VERSION "ETH_Backbone_CAN_STUB_v2.1"

NS_ :

BS_:

BU_: EMS_POLICE_TX EMS_AMB_TX EMS_ALERT_RX ETH_SW WARN_ARB_MGR ADAS_WARN_CTRL NAV_CTX_MGR IVI_GW CHS_GW VAL_SCENARIO_CTRL DOMAIN_BOUNDARY_MGR Vector__XXX

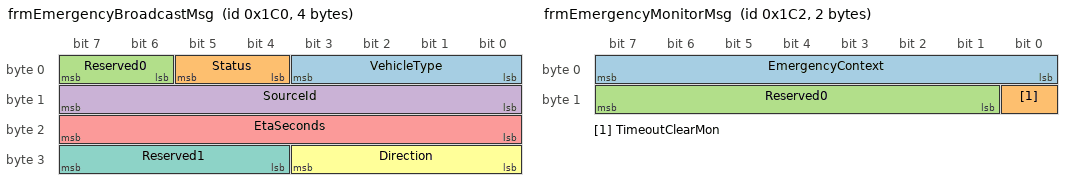
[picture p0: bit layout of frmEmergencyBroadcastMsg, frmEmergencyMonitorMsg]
BO_ 448 frmEmergencyBroadcastMsg: 4 Vector__XXX
 SG_ VehicleType  : 0|4@1+  (1,0) [0|15]  ""    EMS_ALERT_RX
 SG_ Status       : 4|2@1+  (1,0) [0|3]   ""    EMS_ALERT_RX
 SG_ Reserved0    : 6|2@1+  (1,0) [0|0]   ""    Vector__XXX
 SG_ SourceId     : 8|8@1+  (1,0) [0|255] ""    EMS_ALERT_RX
 SG_ EtaSeconds   : 16|8@1+ (1,0) [0|255] "s"   EMS_ALERT_RX
 SG_ Direction    : 24|4@1+ (1,0) [0|15]  ""    EMS_ALERT_RX
 SG_ Reserved1    : 28|4@1+ (1,0) [0|0]   ""    Vector__XXX

BO_ 450 frmEmergencyMonitorMsg: 2 EMS_ALERT_RX
 SG_ EmergencyContext : 0|8@1+ (1,0) [0|255] "" VAL_SCENARIO_CTRL,CHS_GW
 SG_ TimeoutClearMon  : 8|1@1+ (1,0) [0|1]   "" VAL_SCENARIO_CTRL,CHS_GW
 SG_ Reserved0        : 9|7@1+ (1,0) [0|0]   "" Vector__XXX

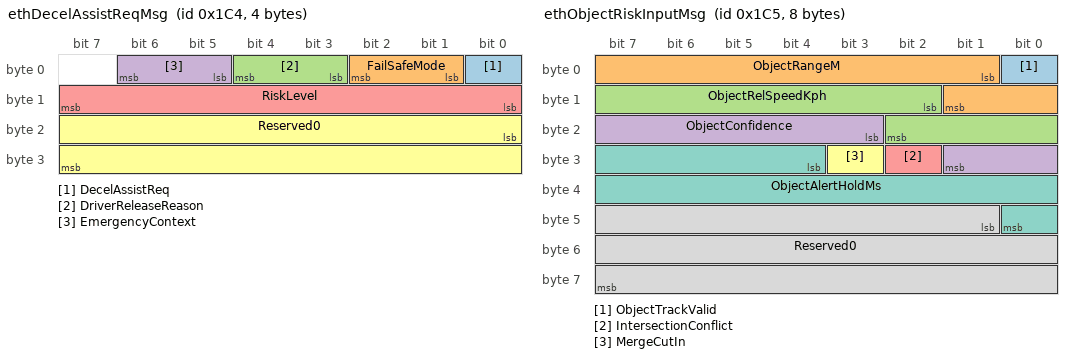
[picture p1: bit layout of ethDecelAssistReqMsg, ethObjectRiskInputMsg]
BO_ 452 ethDecelAssistReqMsg: 4 WARN_ARB_MGR
 SG_ DecelAssistReq      : 0|1@1+ (1,0) [0|1] "" VAL_SCENARIO_CTRL,CHS_GW
 SG_ FailSafeMode        : 1|2@1+ (1,0) [0|2] "" VAL_SCENARIO_CTRL,CHS_GW
 SG_ DriverReleaseReason : 3|2@1+ (1,0) [0|3] "" VAL_SCENARIO_CTRL,CHS_GW
 SG_ EmergencyContext    : 5|2@1+ (1,0) [0|2] "" VAL_SCENARIO_CTRL,CHS_GW
 SG_ RiskLevel           : 8|8@1+ (1,0) [0|100] "" VAL_SCENARIO_CTRL,CHS_GW
 SG_ Reserved0           : 16|16@1+ (1,0) [0|0] "" Vector__XXX

BO_ 453 ethObjectRiskInputMsg: 8 VAL_SCENARIO_CTRL
 SG_ ObjectTrackValid      : 0|1@1+  (1,0) [0|1] "" ADAS_WARN_CTRL
 SG_ ObjectRangeM          : 1|9@1+  (1,0) [0|500] "m" ADAS_WARN_CTRL
 SG_ ObjectRelSpeedKph     : 10|9@1- (1,0) [-200|200] "km/h" ADAS_WARN_CTRL
 SG_ ObjectConfidence      : 19|7@1+ (1,0) [0|100] "%" ADAS_WARN_CTRL
 SG_ IntersectionConflict  : 26|1@1+ (1,0) [0|1] "" ADAS_WARN_CTRL
 SG_ MergeCutIn            : 27|1@1+ (1,0) [0|1] "" ADAS_WARN_CTRL
 SG_ ObjectAlertHoldMs     : 28|13@1+ (1,0) [0|5000] "ms" ADAS_WARN_CTRL
 SG_ Reserved0             : 41|23@1+ (1,0) [0|0] "" Vector__XXX

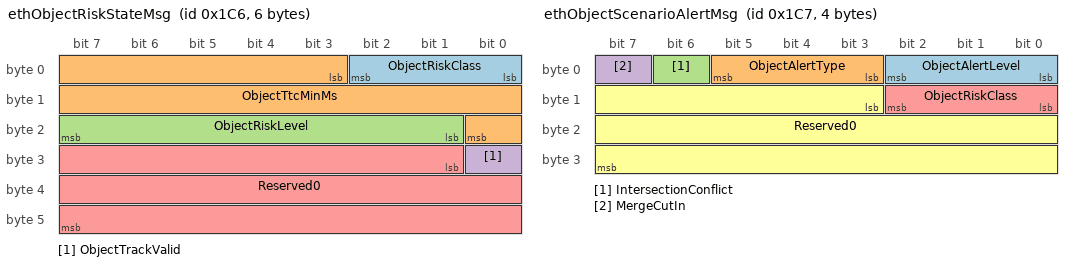
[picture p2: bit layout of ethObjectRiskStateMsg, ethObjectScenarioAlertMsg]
BO_ 454 ethObjectRiskStateMsg: 6 ADAS_WARN_CTRL
 SG_ ObjectRiskClass       : 0|3@1+   (1,0) [0|7] "" WARN_ARB_MGR,VAL_SCENARIO_CTRL
 SG_ ObjectTtcMinMs        : 3|14@1+  (1,0) [0|10000] "ms" WARN_ARB_MGR,VAL_SCENARIO_CTRL
 SG_ ObjectRiskLevel       : 17|7@1+  (1,0) [0|100] "" WARN_ARB_MGR,VAL_SCENARIO_CTRL
 SG_ ObjectTrackValid      : 24|1@1+  (1,0) [0|1] "" WARN_ARB_MGR,VAL_SCENARIO_CTRL
 SG_ Reserved0             : 25|23@1+ (1,0) [0|0] "" Vector__XXX

BO_ 455 ethObjectScenarioAlertMsg: 4 WARN_ARB_MGR
 SG_ ObjectAlertLevel      : 0|3@1+   (1,0) [0|7] "" BODY_GW,IVI_GW,VAL_SCENARIO_CTRL
 SG_ ObjectAlertType       : 3|3@1+   (1,0) [0|7] "" BODY_GW,IVI_GW,VAL_SCENARIO_CTRL
 SG_ IntersectionConflict  : 6|1@1+   (1,0) [0|1] "" BODY_GW,IVI_GW,VAL_SCENARIO_CTRL
 SG_ MergeCutIn            : 7|1@1+   (1,0) [0|1] "" BODY_GW,IVI_GW,VAL_SCENARIO_CTRL
 SG_ ObjectRiskClass       : 8|3@1+   (1,0) [0|7] "" BODY_GW,IVI_GW,VAL_SCENARIO_CTRL
 SG_ Reserved0             : 11|21@1+ (1,0) [0|0] "" Vector__XXX

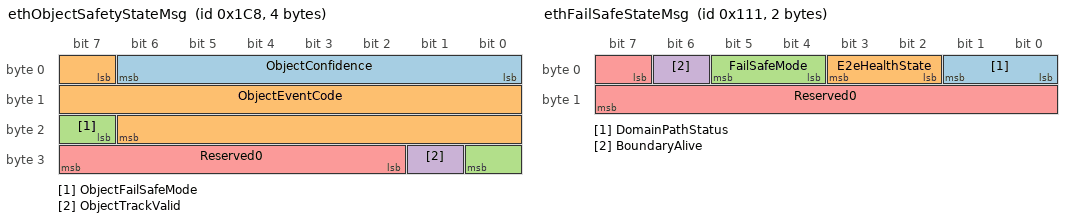
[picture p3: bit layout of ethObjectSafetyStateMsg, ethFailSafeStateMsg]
BO_ 456 ethObjectSafetyStateMsg: 4 DOMAIN_BOUNDARY_MGR
 SG_ ObjectConfidence      : 0|7@1+   (1,0) [0|100] "%" WARN_ARB_MGR,VAL_SCENARIO_CTRL,EMS_ALERT_RX
 SG_ ObjectEventCode       : 7|16@1+  (1,0) [0|65535] "" WARN_ARB_MGR,VAL_SCENARIO_CTRL,EMS_ALERT_RX
 SG_ ObjectFailSafeMode    : 23|2@1+  (1,0) [0|2] "" WARN_ARB_MGR,VAL_SCENARIO_CTRL,EMS_ALERT_RX
 SG_ ObjectTrackValid      : 25|1@1+  (1,0) [0|1] "" WARN_ARB_MGR,VAL_SCENARIO_CTRL,EMS_ALERT_RX
 SG_ Reserved0             : 26|6@1+  (1,0) [0|0] "" Vector__XXX

BO_ 273 ethFailSafeStateMsg: 2 DOMAIN_BOUNDARY_MGR
 SG_ DomainPathStatus : 0|2@1+ (1,0) [0|2] "" WARN_ARB_MGR,VAL_SCENARIO_CTRL
 SG_ E2eHealthState   : 2|2@1+ (1,0) [0|2] "" WARN_ARB_MGR,VAL_SCENARIO_CTRL
 SG_ FailSafeMode     : 4|2@1+ (1,0) [0|2] "" WARN_ARB_MGR,VAL_SCENARIO_CTRL
 SG_ BoundaryAlive    : 6|1@1+ (1,0) [0|1] "" WARN_ARB_MGR,VAL_SCENARIO_CTRL
 SG_ Reserved0        : 7|9@1+ (1,0) [0|0] "" Vector__XXX

CM_ BO_ 448 "E100: Emergency vehicle broadcast. Sent by EMS_POLICE_TX (type=1) or EMS_AMB_TX (type=2) on ETH backbone (ch5). Received by EMS_ALERT_RX for priority arbitration. STUB: This file substitutes CANoe.Ethernet backbone using CAN ch5. Delete this file and replace with Ethernet network when CANoe.Ethernet license is available. Interface spec: 0303_Communication_Specification.md E100.";
CM_ SG_ 448 VehicleType  "1=POLICE 2=AMBULANCE";
CM_ SG_ 448 Status       "0=CLEAR 1=ACTIVE";
CM_ SG_ 448 SourceId     "Unique vehicle source ID for tiebreaker.";
CM_ SG_ 448 EtaSeconds   "Estimated time of arrival in seconds. Lower = higher priority.";
CM_ SG_ 448 Direction    "0=UNKNOWN 1=FRONT 2=REAR 3=SIDE";
CM_ BO_ 450 "E562: Emergency monitor shadow. Produced by EMS_ALERT_RX on ETH backbone. Moved from chassis_can v2 architecture refactor.";
CM_ SG_ 450 EmergencyContext "Active emergency type mirrored from Core sysvar.";
CM_ SG_ 450 TimeoutClearMon  "1=timeout clear pulse active.";
CM_ BO_ 452 "E788: Deceleration assist request frame. Produced by WARN_ARB_MGR (Req_121~123).";
CM_ SG_ 452 DecelAssistReq "0=off 1=active.";
CM_ SG_ 452 FailSafeMode "0=normal 1=degraded 2=blocked.";
CM_ SG_ 452 DriverReleaseReason "0=none 1=steering 2=brake 3=failsafe.";
CM_ BO_ 453 "E213: Object risk input frame (SIL harness path). Produced by VAL_SCENARIO_CTRL and consumed by ADAS_WARN_CTRL.";
CM_ SG_ 453 ObjectTrackValid "Object track validity.";
CM_ SG_ 453 ObjectRangeM "Representative object range in meters.";
CM_ SG_ 453 ObjectRelSpeedKph "Relative speed of representative object (negative=closing).";
CM_ SG_ 453 ObjectConfidence "Object confidence score in percent.";
CM_ SG_ 453 IntersectionConflict "1=intersection lateral conflict context.";
CM_ SG_ 453 MergeCutIn "1=merge/cut-in conflict context.";
CM_ SG_ 453 ObjectAlertHoldMs "Conservative hold time for temporary track loss.";
CM_ BO_ 454 "E214: Object risk state frame. Produced by ADAS_WARN_CTRL for object TTC/risk arbitration.";
CM_ SG_ 454 ObjectRiskClass "0=none .. 5=critical object risk class.";
CM_ SG_ 454 ObjectTtcMinMs "Representative object minimum TTC in ms.";
CM_ SG_ 454 ObjectRiskLevel "Normalized object risk level (0..100).";
CM_ BO_ 455 "E215: Object scenario alert frame. Produced by WARN_ARB_MGR for object-context alert sharing.";
CM_ SG_ 455 ObjectAlertLevel "Object-context selected alert level.";
CM_ SG_ 455 ObjectAlertType "Object-context selected alert type.";
CM_ BO_ 456 "E216: Object safety state frame. Produced by DOMAIN_BOUNDARY_MGR for confidence/failsafe/event trace.";
CM_ SG_ 456 ObjectEventCode "Object alert event code (Req_138 traceability).";
CM_ SG_ 456 ObjectFailSafeMode "Object path fail-safe mode mirror.";
CM_ BO_ 273 "E789: Fail-safe state frame. Produced by DOMAIN_BOUNDARY_MGR (Req_124).";
CM_ SG_ 273 DomainPathStatus "0=normal 1=degraded 2=failed.";
CM_ SG_ 273 E2eHealthState "0=failed 1=degraded 2=healthy.";
CM_ SG_ 273 FailSafeMode "0=normal 1=degraded 2=blocked.";

BA_DEF_ BO_ "GenMsgCycleTime" INT 0 10000;
BA_DEF_DEF_ "GenMsgCycleTime" 0;
BA_ "GenMsgCycleTime" BO_ 450 100;
BA_ "GenMsgCycleTime" BO_ 452 50;
BA_ "GenMsgCycleTime" BO_ 453 100;
BA_ "GenMsgCycleTime" BO_ 454 100;
BA_ "GenMsgCycleTime" BO_ 455 50;
BA_ "GenMsgCycleTime" BO_ 456 100;
BA_ "GenMsgCycleTime" BO_ 273 300;

VAL_ 448 VehicleType 0 "NONE" 1 "POLICE" 2 "AMBULANCE";
VAL_ 448 Status 0 "CLEAR" 1 "ACTIVE";
VAL_ 448 Direction 0 "UNKNOWN" 1 "FRONT" 2 "REAR" 3 "SIDE";
VAL_ 450 TimeoutClearMon 0 "NoClear" 1 "Clear";
VAL_ 452 DecelAssistReq 0 "OFF" 1 "ON";
VAL_ 452 DriverReleaseReason 0 "NONE" 1 "STEER" 2 "BRAKE" 3 "FAILSAFE";
VAL_ 453 ObjectTrackValid 0 "INVALID" 1 "VALID";
VAL_ 453 IntersectionConflict 0 "NO" 1 "YES";
VAL_ 453 MergeCutIn 0 "NO" 1 "YES";
VAL_ 454 ObjectTrackValid 0 "INVALID" 1 "VALID";
VAL_ 455 IntersectionConflict 0 "NO" 1 "YES";
VAL_ 455 MergeCutIn 0 "NO" 1 "YES";
VAL_ 456 ObjectFailSafeMode 0 "NORMAL" 1 "DEGRADED" 2 "BLOCKED";
VAL_ 456 ObjectTrackValid 0 "INVALID" 1 "VALID";
VAL_ 273 DomainPathStatus 0 "NORMAL" 1 "DEGRADED" 2 "FAILED";
VAL_ 273 E2eHealthState 0 "FAILED" 1 "DEGRADED" 2 "HEALTHY";
VAL_ 273 FailSafeMode 0 "NORMAL" 1 "DEGRADED" 2 "BLOCKED";
